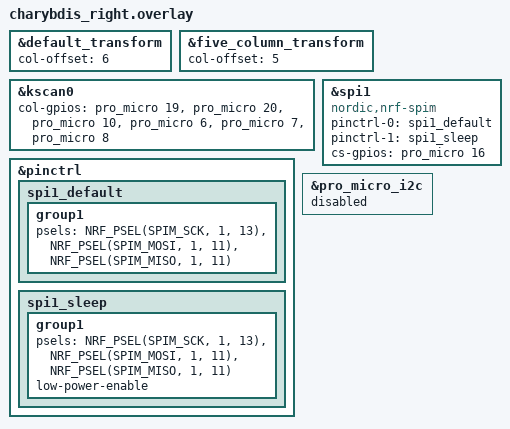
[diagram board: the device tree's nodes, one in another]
/*
 * Copyright (c) 2020 ZMK Contributors
 *
 * SPDX-License-Identifier: MIT
 */
 
#include "charybdis.dtsi"
#include "pmw3610.dtsi"
#include <zephyr/dt-bindings/input/input-event-codes.h>
#include <dt-bindings/zmk/input_transform.h>


&default_transform {
    col-offset = <6>;
};

&five_column_transform {
    col-offset = <5>;
};

&kscan0 {
	col-gpios
		= <&pro_micro 19 (GPIO_ACTIVE_HIGH | GPIO_PULL_DOWN)>
		, <&pro_micro 20 (GPIO_ACTIVE_HIGH | GPIO_PULL_DOWN)>
		, <&pro_micro 10 (GPIO_ACTIVE_HIGH | GPIO_PULL_DOWN)>
		, <&pro_micro 6 (GPIO_ACTIVE_HIGH | GPIO_PULL_DOWN)>
		, <&pro_micro 7 (GPIO_ACTIVE_HIGH | GPIO_PULL_DOWN)>
		, <&pro_micro 8 (GPIO_ACTIVE_HIGH | GPIO_PULL_DOWN)>
		;
};

&pinctrl {
    spi1_default: spi1_default {
        group1 {
            psels = <NRF_PSEL(SPIM_SCK, 1, 13)>,
                <NRF_PSEL(SPIM_MOSI, 1, 11)>,
                <NRF_PSEL(SPIM_MISO, 1, 11)>;
        };
    };
    spi1_sleep: spi1_sleep {
        group1 {
            psels = <NRF_PSEL(SPIM_SCK, 1, 13)>,
                <NRF_PSEL(SPIM_MOSI, 1, 11)>,
                <NRF_PSEL(SPIM_MISO, 1, 11)>;
            low-power-enable;
        };
    };
};

nice_view_spi: &spi1 {
    compatible = "nordic,nrf-spim";
    pinctrl-0 = <&spi1_default>;
    pinctrl-1 = <&spi1_sleep>;
    pinctrl-names = "default", "sleep";
    cs-gpios = <&pro_micro 16 GPIO_ACTIVE_HIGH>; //HAND
};

&pro_micro_i2c {
    status = "disabled";
};








